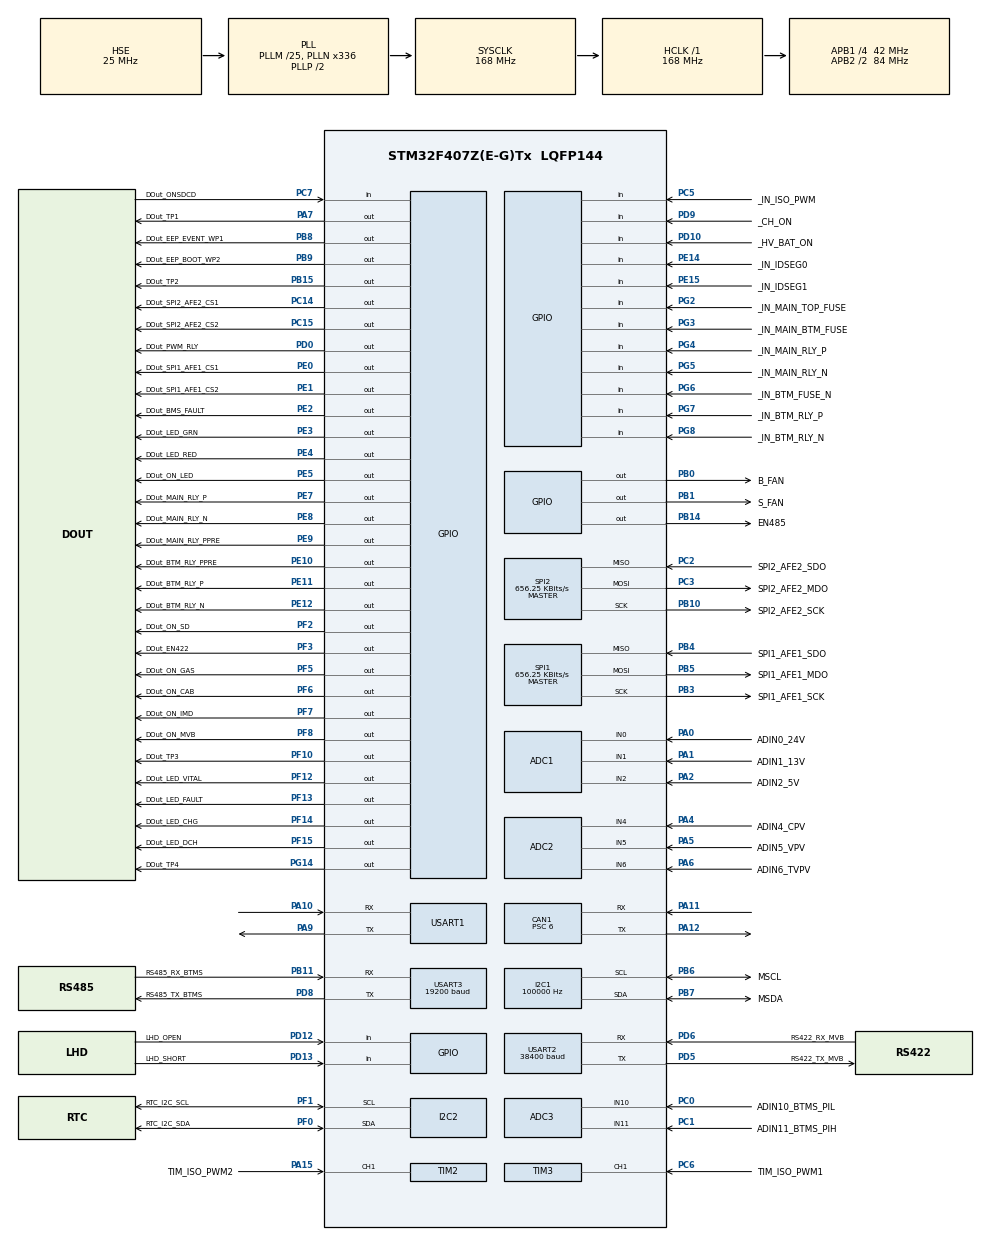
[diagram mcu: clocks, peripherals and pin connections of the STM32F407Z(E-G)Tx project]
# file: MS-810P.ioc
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ADC1.Channel-1\#ChannelRegularConversion=ADC_CHANNEL_0
ADC1.Channel-2\#ChannelRegularConversion=ADC_CHANNEL_1
ADC1.Channel-3\#ChannelRegularConversion=ADC_CHANNEL_2
ADC1.Channel-4\#ChannelRegularConversion=ADC_CHANNEL_VREFINT
ADC1.ClockPrescaler=ADC_CLOCK_SYNC_PCLK_DIV4
ADC1.ContinuousConvMode=ENABLE
ADC1.DMAContinuousRequests=ENABLE
ADC1.EOCSelection=ADC_EOC_SEQ_CONV
ADC1.NbrOfConversion=4
ADC1.NbrOfConversionFlag=1
ADC1.Rank-1\#ChannelRegularConversion=1
ADC1.Rank-2\#ChannelRegularConversion=2
ADC1.Rank-3\#ChannelRegularConversion=3
ADC1.Rank-4\#ChannelRegularConversion=4
ADC1.SamplingTime-1\#ChannelRegularConversion=ADC_SAMPLETIME_480CYCLES
ADC1.SamplingTime-2\#ChannelRegularConversion=ADC_SAMPLETIME_480CYCLES
ADC1.SamplingTime-3\#ChannelRegularConversion=ADC_SAMPLETIME_480CYCLES
ADC1.SamplingTime-4\#ChannelRegularConversion=ADC_SAMPLETIME_480CYCLES
ADC1.ScanConvMode=ENABLE
ADC1.master=1
ADC2.Channel-2\#ChannelRegularConversion=ADC_CHANNEL_4
ADC2.Channel-3\#ChannelRegularConversion=ADC_CHANNEL_5
ADC2.Channel-4\#ChannelRegularConversion=ADC_CHANNEL_6
ADC2.ClockPrescaler=ADC_CLOCK_SYNC_PCLK_DIV4
ADC2.ContinuousConvMode=ENABLE
ADC2.DMAContinuousRequests=ENABLE
ADC2.EOCSelection=ADC_EOC_SEQ_CONV
ADC2.NbrOfConversion=3
ADC2.NbrOfConversionFlag=1
ADC2.Rank-2\#ChannelRegularConversion=1
ADC2.Rank-3\#ChannelRegularConversion=2
ADC2.Rank-4\#ChannelRegularConversion=3
ADC2.SamplingTime-2\#ChannelRegularConversion=ADC_SAMPLETIME_480CYCLES
ADC2.SamplingTime-3\#ChannelRegularConversion=ADC_SAMPLETIME_480CYCLES
ADC2.SamplingTime-4\#ChannelRegularConversion=ADC_SAMPLETIME_480CYCLES
ADC2.ScanConvMode=ENABLE
ADC3.Channel-1\#ChannelRegularConversion=ADC_CHANNEL_10
ADC3.Channel-2\#ChannelRegularConversion=ADC_CHANNEL_11
ADC3.ClockPrescaler=ADC_CLOCK_SYNC_PCLK_DIV4
ADC3.ContinuousConvMode=ENABLE
ADC3.DMAContinuousRequests=ENABLE
ADC3.EOCSelection=ADC_EOC_SEQ_CONV
ADC3.NbrOfConversion=2
ADC3.NbrOfConversionFlag=1
ADC3.Rank-1\#ChannelRegularConversion=1
ADC3.Rank-2\#ChannelRegularConversion=2
ADC3.SamplingTime-1\#ChannelRegularConversion=ADC_SAMPLETIME_480CYCLES
ADC3.SamplingTime-2\#ChannelRegularConversion=ADC_SAMPLETIME_480CYCLES
ADC3.ScanConvMode=ENABLE
CAN1.BS1=CAN_BS1_11TQ
CAN1.BS2=CAN_BS2_2TQ
CAN1.CalculateBaudRate=500000
CAN1.CalculateTimeBit=2000
CAN1.CalculateTimeQuantum=142.85714285714286
CAN1.Prescaler=6
Dma.ADC1.7.Direction=DMA_PERIPH_TO_MEMORY
Dma.ADC1.7.FIFOMode=DMA_FIFOMODE_DISABLE
Dma.ADC1.7.Instance=DMA2_Stream4
Dma.ADC1.7.MemDataAlignment=DMA_MDATAALIGN_HALFWORD
Dma.ADC1.7.MemInc=DMA_MINC_ENABLE
Dma.ADC1.7.Mode=DMA_CIRCULAR
Dma.ADC1.7.PeriphDataAlignment=DMA_PDATAALIGN_HALFWORD
Dma.ADC1.7.PeriphInc=DMA_PINC_DISABLE
Dma.ADC1.7.Priority=DMA_PRIORITY_LOW
Dma.ADC2.10.Direction=DMA_PERIPH_TO_MEMORY
Dma.ADC2.10.FIFOMode=DMA_FIFOMODE_DISABLE
Dma.ADC2.10.Instance=DMA2_Stream2
Dma.ADC2.10.MemDataAlignment=DMA_MDATAALIGN_HALFWORD
Dma.ADC2.10.MemInc=DMA_MINC_ENABLE
Dma.ADC2.10.Mode=DMA_CIRCULAR
Dma.ADC2.10.PeriphDataAlignment=DMA_PDATAALIGN_HALFWORD
Dma.ADC2.10.PeriphInc=DMA_PINC_DISABLE
Dma.ADC2.10.Priority=DMA_PRIORITY_LOW
Dma.ADC3.11.Direction=DMA_PERIPH_TO_MEMORY
Dma.ADC3.11.FIFOMode=DMA_FIFOMODE_DISABLE
Dma.ADC3.11.Instance=DMA2_Stream1
Dma.ADC3.11.MemDataAlignment=DMA_MDATAALIGN_HALFWORD
Dma.ADC3.11.MemInc=DMA_MINC_ENABLE
Dma.ADC3.11.Mode=DMA_CIRCULAR
Dma.ADC3.11.PeriphDataAlignment=DMA_PDATAALIGN_HALFWORD
Dma.ADC3.11.PeriphInc=DMA_PINC_DISABLE
Dma.ADC3.11.Priority=DMA_PRIORITY_LOW
Dma.Request0=SPI1_TX
Dma.Request1=SPI1_RX
Dma.Request10=ADC2
Dma.Request11=ADC3
Dma.Request2=SPI2_TX
Dma.Request3=SPI2_RX
Dma.Request4=USART2_TX
Dma.Request5=USART2_RX
Dma.Request6=USART3_RX
Dma.Request7=ADC1
Dma.Request8=USART1_RX
Dma.Request9=USART1_TX
Dma.SPI1_RX.1.Direction=DMA_PERIPH_TO_MEMORY
Dma.SPI1_RX.1.FIFOMode=DMA_FIFOMODE_DISABLE
Dma.SPI1_RX.1.Instance=DMA2_Stream0
Dma.SPI1_RX.1.MemDataAlignment=DMA_MDATAALIGN_BYTE
Dma.SPI1_RX.1.MemInc=DMA_MINC_ENABLE
Dma.SPI1_RX.1.Mode=DMA_NORMAL
Dma.SPI1_RX.1.PeriphDataAlignment=DMA_PDATAALIGN_BYTE
Dma.SPI1_RX.1.PeriphInc=DMA_PINC_DISABLE
Dma.SPI1_RX.1.Priority=DMA_PRIORITY_LOW
Dma.SPI1_TX.0.Direction=DMA_MEMORY_TO_PERIPH
Dma.SPI1_TX.0.FIFOMode=DMA_FIFOMODE_DISABLE
Dma.SPI1_TX.0.Instance=DMA2_Stream3
Dma.SPI1_TX.0.MemDataAlignment=DMA_MDATAALIGN_BYTE
Dma.SPI1_TX.0.MemInc=DMA_MINC_ENABLE
Dma.SPI1_TX.0.Mode=DMA_NORMAL
Dma.SPI1_TX.0.PeriphDataAlignment=DMA_PDATAALIGN_BYTE
Dma.SPI1_TX.0.PeriphInc=DMA_PINC_DISABLE
Dma.SPI1_TX.0.Priority=DMA_PRIORITY_LOW
Dma.SPI2_RX.3.Direction=DMA_PERIPH_TO_MEMORY
Dma.SPI2_RX.3.FIFOMode=DMA_FIFOMODE_DISABLE
Dma.SPI2_RX.3.Instance=DMA1_Stream3
Dma.SPI2_RX.3.MemDataAlignment=DMA_MDATAALIGN_BYTE
Dma.SPI2_RX.3.MemInc=DMA_MINC_ENABLE
Dma.SPI2_RX.3.Mode=DMA_NORMAL
Dma.SPI2_RX.3.PeriphDataAlignment=DMA_PDATAALIGN_BYTE
Dma.SPI2_RX.3.PeriphInc=DMA_PINC_DISABLE
Dma.SPI2_RX.3.Priority=DMA_PRIORITY_LOW
Dma.SPI2_TX.2.Direction=DMA_MEMORY_TO_PERIPH
Dma.SPI2_TX.2.FIFOMode=DMA_FIFOMODE_DISABLE
Dma.SPI2_TX.2.Instance=DMA1_Stream4
Dma.SPI2_TX.2.MemDataAlignment=DMA_MDATAALIGN_BYTE
Dma.SPI2_TX.2.MemInc=DMA_MINC_ENABLE
Dma.SPI2_TX.2.Mode=DMA_NORMAL
Dma.SPI2_TX.2.PeriphDataAlignment=DMA_PDATAALIGN_BYTE
Dma.SPI2_TX.2.PeriphInc=DMA_PINC_DISABLE
Dma.SPI2_TX.2.Priority=DMA_PRIORITY_LOW
Dma.USART1_RX.8.Direction=DMA_PERIPH_TO_MEMORY
Dma.USART1_RX.8.FIFOMode=DMA_FIFOMODE_DISABLE
Dma.USART1_RX.8.Instance=DMA2_Stream5
Dma.USART1_RX.8.MemDataAlignment=DMA_MDATAALIGN_BYTE
Dma.USART1_RX.8.MemInc=DMA_MINC_ENABLE
Dma.USART1_RX.8.Mode=DMA_CIRCULAR
Dma.USART1_RX.8.PeriphDataAlignment=DMA_PDATAALIGN_BYTE
Dma.USART1_RX.8.PeriphInc=DMA_PINC_DISABLE
Dma.USART1_RX.8.Priority=DMA_PRIORITY_LOW
Dma.USART1_TX.9.Direction=DMA_MEMORY_TO_PERIPH
Dma.USART1_TX.9.FIFOMode=DMA_FIFOMODE_DISABLE
Dma.USART1_TX.9.Instance=DMA2_Stream7
Dma.USART1_TX.9.MemDataAlignment=DMA_MDATAALIGN_BYTE
Dma.USART1_TX.9.MemInc=DMA_MINC_ENABLE
Dma.USART1_TX.9.Mode=DMA_NORMAL
Dma.USART1_TX.9.PeriphDataAlignment=DMA_PDATAALIGN_BYTE
Dma.USART1_TX.9.PeriphInc=DMA_PINC_DISABLE
Dma.USART1_TX.9.Priority=DMA_PRIORITY_LOW
Dma.USART2_RX.5.Direction=DMA_PERIPH_TO_MEMORY
Dma.USART2_RX.5.FIFOMode=DMA_FIFOMODE_DISABLE
Dma.USART2_RX.5.Instance=DMA1_Stream5
Dma.USART2_RX.5.MemDataAlignment=DMA_MDATAALIGN_BYTE
Dma.USART2_RX.5.MemInc=DMA_MINC_ENABLE
Dma.USART2_RX.5.Mode=DMA_NORMAL
Dma.USART2_RX.5.PeriphDataAlignment=DMA_PDATAALIGN_BYTE
Dma.USART2_RX.5.PeriphInc=DMA_PINC_DISABLE
Dma.USART2_RX.5.Priority=DMA_PRIORITY_LOW
Dma.USART2_TX.4.Direction=DMA_MEMORY_TO_PERIPH
Dma.USART2_TX.4.FIFOMode=DMA_FIFOMODE_DISABLE
Dma.USART2_TX.4.Instance=DMA1_Stream6
Dma.USART2_TX.4.MemDataAlignment=DMA_MDATAALIGN_BYTE
Dma.USART2_TX.4.MemInc=DMA_MINC_ENABLE
Dma.USART2_TX.4.Mode=DMA_NORMAL
Dma.USART2_TX.4.PeriphDataAlignment=DMA_PDATAALIGN_BYTE
Dma.USART2_TX.4.PeriphInc=DMA_PINC_DISABLE
Dma.USART2_TX.4.Priority=DMA_PRIORITY_LOW
Dma.USART3_RX.6.Direction=DMA_PERIPH_TO_MEMORY
Dma.USART3_RX.6.FIFOMode=DMA_FIFOMODE_DISABLE
Dma.USART3_RX.6.Instance=DMA1_Stream1
Dma.USART3_RX.6.MemDataAlignment=DMA_MDATAALIGN_BYTE
Dma.USART3_RX.6.MemInc=DMA_MINC_ENABLE
Dma.USART3_RX.6.Mode=DMA_NORMAL
Dma.USART3_RX.6.PeriphDataAlignment=DMA_PDATAALIGN_BYTE
Dma.USART3_RX.6.PeriphInc=DMA_PINC_DISABLE
Dma.USART3_RX.6.Priority=DMA_PRIORITY_LOW
I2C1.ClockSpeed=100000
I2C1.I2C_Mode=I2C_Standard
Mcu.Family=STM32F4
Mcu.Name=STM32F407Z(E-G)Tx
Mcu.Package=LQFP144
NVIC.CAN1_RX0_IRQn=true\:4\:0\:true\:false\:true\:true\:true\:true
NVIC.CAN1_TX_IRQn=true\:4\:0\:true\:false\:true\:true\:true\:true
NVIC.DMA1_Stream1_IRQn=true\:6\:0\:true\:false\:true\:false\:true\:true
NVIC.DMA1_Stream3_IRQn=true\:3\:0\:true\:false\:true\:false\:true\:true
NVIC.DMA1_Stream4_IRQn=true\:3\:0\:true\:false\:true\:false\:true\:true
NVIC.DMA1_Stream5_IRQn=true\:6\:0\:true\:false\:true\:false\:true\:true
NVIC.DMA1_Stream6_IRQn=true\:6\:0\:true\:false\:true\:false\:true\:true
NVIC.DMA2_Stream0_IRQn=true\:3\:0\:true\:false\:true\:false\:true\:true
NVIC.DMA2_Stream1_IRQn=true\:2\:0\:true\:false\:true\:false\:true\:true
NVIC.DMA2_Stream2_IRQn=true\:2\:0\:true\:false\:true\:false\:true\:true
NVIC.DMA2_Stream3_IRQn=true\:3\:0\:true\:false\:true\:false\:true\:true
NVIC.DMA2_Stream4_IRQn=true\:2\:0\:true\:false\:true\:false\:true\:true
NVIC.DMA2_Stream5_IRQn=true\:6\:0\:true\:false\:true\:false\:true\:true
NVIC.DMA2_Stream7_IRQn=true\:6\:0\:true\:false\:true\:false\:true\:true
NVIC.I2C1_EV_IRQn=true\:5\:0\:true\:false\:true\:true\:true\:true
NVIC.I2C2_ER_IRQn=true\:5\:0\:true\:false\:true\:true\:true\:true
NVIC.I2C2_EV_IRQn=true\:5\:0\:true\:false\:true\:true\:true\:true
NVIC.PriorityGroup=NVIC_PRIORITYGROUP_4
NVIC.TIM1_UP_TIM10_IRQn=true\:1\:0\:true\:false\:true\:true\:true\:true
NVIC.USART1_IRQn=true\:6\:0\:true\:false\:true\:true\:true\:true
NVIC.USART2_IRQn=true\:6\:0\:true\:false\:true\:true\:true\:true
NVIC.USART3_IRQn=true\:6\:0\:true\:false\:true\:true\:true\:true
PA0-WKUP.GPIO_Label=ADIN0_24V
PA0-WKUP.Signal=ADCx_IN0
PA1.GPIO_Label=ADIN1_13V
PA1.Signal=ADCx_IN1
PA10.GPIO_ModeDefaultPP=GPIO_MODE_AF_PP
PA10.GPIO_PuPd=GPIO_NOPULL
PA10.GPIO_Speed=GPIO_SPEED_FREQ_VERY_HIGH
PA10.Mode=Asynchronous
PA10.Signal=USART1_RX
PA11.Mode=CAN_Activate
PA11.Signal=CAN1_RX
PA12.Mode=CAN_Activate
PA12.Signal=CAN1_TX
PA13.Mode=Serial_Wire
PA13.Signal=SYS_JTMS-SWDIO
PA14.Mode=Serial_Wire
PA14.Signal=SYS_JTCK-SWCLK
PA15.GPIO_Label=TIM_ISO_PWM2
PA15.GPIO_ModeDefaultPP=GPIO_MODE_AF_PP
PA15.GPIO_PuPd=GPIO_NOPULL
PA15.GPIO_Speed=GPIO_SPEED_FREQ_LOW
PA15.Signal=S_TIM2_CH1_ETR
PA2.GPIO_Label=ADIN2_5V
PA2.Signal=ADCx_IN2
PA4.GPIO_Label=ADIN4_CPV
PA4.Signal=ADCx_IN4
PA5.GPIO_Label=ADIN5_VPV
PA5.Signal=ADCx_IN5
PA6.GPIO_Label=ADIN6_TVPV
PA6.Signal=ADCx_IN6
PA7.GPIO_Label=DOut_TP1
PA7.Signal=GPIO_Output
PA9.GPIO_ModeDefaultPP=GPIO_MODE_AF_PP
PA9.GPIO_PuPd=GPIO_NOPULL
PA9.GPIO_Speed=GPIO_SPEED_FREQ_VERY_HIGH
PA9.Mode=Asynchronous
PA9.Signal=USART1_TX
PB0.GPIO_Label=B_FAN
PB0.Signal=GPIO_Output
PB1.GPIO_Label=S_FAN
PB1.Signal=GPIO_Output
PB10.GPIO_Label=SPI2_AFE2_SCK
PB10.Mode=Full_Duplex_Master
PB10.Signal=SPI2_SCK
PB11.GPIO_Label=RS485_RX_BTMS
PB11.Mode=Asynchronous
PB11.Signal=USART3_RX
PB14.GPIO_Label=EN485
PB14.Signal=GPIO_Output
PB15.GPIO_Label=DOut_TP2
PB15.Signal=GPIO_Output
PB3.GPIO_Label=SPI1_AFE1_SCK
PB3.Mode=Full_Duplex_Master
PB3.Signal=SPI1_SCK
PB4.GPIO_Label=SPI1_AFE1_SDO
PB4.Mode=Full_Duplex_Master
PB4.Signal=SPI1_MISO
PB5.GPIO_Label=SPI1_AFE1_MDO
PB5.Mode=Full_Duplex_Master
PB5.Signal=SPI1_MOSI
PB6.GPIO_Label=MSCL
PB6.Mode=I2C
PB6.Signal=I2C1_SCL
PB7.GPIO_Label=MSDA
PB7.Mode=I2C
PB7.Signal=I2C1_SDA
PB8.GPIO_Label=DOut_EEP_EVENT_WP1
PB8.Signal=GPIO_Output
PB9.GPIO_Label=DOut_EEP_BOOT_WP2
PB9.Signal=GPIO_Output
PC0.GPIO_Label=ADIN10_BTMS_PIL
PC0.Signal=ADCx_IN10
PC1.GPIO_Label=ADIN11_BTMS_PIH
PC1.Signal=ADCx_IN11
PC14-OSC32_IN.GPIO_Label=DOut_SPI2_AFE2_CS1
PC14-OSC32_IN.Signal=GPIO_Output
PC15-OSC32_OUT.GPIO_Label=DOut_SPI2_AFE2_CS2
PC15-OSC32_OUT.Signal=GPIO_Output
PC2.GPIO_Label=SPI2_AFE2_SDO
PC2.Mode=Full_Duplex_Master
PC2.Signal=SPI2_MISO
PC3.GPIO_Label=SPI2_AFE2_MDO
PC3.Mode=Full_Duplex_Master
PC3.Signal=SPI2_MOSI
PC5.GPIO_Label=_IN_ISO_PWM
PC5.Signal=GPIO_Input
PC6.GPIO_Label=TIM_ISO_PWM1
PC6.Signal=S_TIM3_CH1
PC7.GPIO_Label=DOut_ONSDCD
PC7.Signal=GPIO_Input
PD0.GPIO_Label=DOut_PWM_RLY
PD0.Signal=GPIO_Output
PD10.GPIO_Label=_HV_BAT_ON
PD10.Signal=GPIO_Input
PD12.GPIO_Label=LHD_OPEN
PD12.Signal=GPIO_Input
PD13.GPIO_Label=LHD_SHORT
PD13.Signal=GPIO_Input
PD5.GPIO_Label=RS422_TX_MVB
PD5.Mode=Asynchronous
PD5.Signal=USART2_TX
PD6.GPIO_Label=RS422_RX_MVB
PD6.Mode=Asynchronous
PD6.Signal=USART2_RX
PD8.GPIO_Label=RS485_TX_BTMS
PD8.Mode=Asynchronous
PD8.Signal=USART3_TX
PD9.GPIO_Label=_CH_ON
PD9.Signal=GPIO_Input
PE0.GPIO_Label=DOut_SPI1_AFE1_CS1
PE0.Signal=GPIO_Output
PE1.GPIO_Label=DOut_SPI1_AFE1_CS2
PE1.Signal=GPIO_Output
PE10.GPIO_Label=DOut_BTM_RLY_PPRE
PE10.Signal=GPIO_Output
PE11.GPIO_Label=DOut_BTM_RLY_P
PE11.Signal=GPIO_Output
PE12.GPIO_Label=DOut_BTM_RLY_N
PE12.Signal=GPIO_Output
PE14.GPIO_Label=_IN_IDSEG0
PE14.Signal=GPIO_Input
PE15.GPIO_Label=_IN_IDSEG1
PE15.Signal=GPIO_Input
PE2.GPIO_Label=DOut_BMS_FAULT
PE2.Signal=GPIO_Output
PE3.GPIO_Label=DOut_LED_GRN
PE3.Signal=GPIO_Output
PE4.GPIO_Label=DOut_LED_RED
PE4.Signal=GPIO_Output
PE5.GPIO_Label=DOut_ON_LED
PE5.Signal=GPIO_Output
PE7.GPIO_Label=DOut_MAIN_RLY_P
PE7.Signal=GPIO_Output
PE8.GPIO_Label=DOut_MAIN_RLY_N
PE8.Signal=GPIO_Output
PE9.GPIO_Label=DOut_MAIN_RLY_PPRE
PE9.Signal=GPIO_Output
PF0.GPIO_Label=RTC_I2C_SDA
PF0.Mode=I2C
PF0.Signal=I2C2_SDA
PF1.GPIO_Label=RTC_I2C_SCL
PF1.Mode=I2C
PF1.Signal=I2C2_SCL
PF10.GPIO_Label=DOut_TP3
PF10.Signal=GPIO_Output
PF12.GPIO_Label=DOut_LED_VITAL
PF12.Signal=GPIO_Output
PF13.GPIO_Label=DOut_LED_FAULT
PF13.Signal=GPIO_Output
PF14.GPIO_Label=DOut_LED_CHG
PF14.Signal=GPIO_Output
PF15.GPIO_Label=DOut_LED_DCH
PF15.Signal=GPIO_Output
PF2.GPIO_Label=DOut_ON_SD
PF2.Signal=GPIO_Output
PF3.GPIO_Label=DOut_EN422
PF3.Signal=GPIO_Output
PF5.GPIO_Label=DOut_ON_GAS
PF5.Signal=GPIO_Output
PF6.GPIO_Label=DOut_ON_CAB
PF6.Signal=GPIO_Output
PF7.GPIO_Label=DOut_ON_IMD
PF7.Signal=GPIO_Output
PF8.GPIO_Label=DOut_ON_MVB
PF8.Signal=GPIO_Output
PG14.GPIO_Label=DOut_TP4
PG14.Signal=GPIO_Output
PG2.GPIO_Label=_IN_MAIN_TOP_FUSE
PG2.Signal=GPIO_Input
PG3.GPIO_Label=_IN_MAIN_BTM_FUSE
PG3.Signal=GPIO_Input
PG4.GPIO_Label=_IN_MAIN_RLY_P
PG4.Signal=GPIO_Input
PG5.GPIO_Label=_IN_MAIN_RLY_N
PG5.Signal=GPIO_Input
PG6.GPIO_Label=_IN_BTM_FUSE_N
PG6.Signal=GPIO_Input
PG7.GPIO_Label=_IN_BTM_RLY_P
PG7.Signal=GPIO_Input
PG8.GPIO_Label=_IN_BTM_RLY_N
PG8.Signal=GPIO_Input
PH0-OSC_IN.Mode=HSE-External-Oscillator
PH0-OSC_IN.Signal=RCC_OSC_IN
PH1-OSC_OUT.Mode=HSE-External-Oscillator
PH1-OSC_OUT.Signal=RCC_OSC_OUT
ProjectManager.HeapSize=0x200
ProjectManager.StackSize=0x400
ProjectManager.TargetToolchain=STM32CubeIDE
RCC.48MHZClocksFreq_Value=48000000
RCC.AHBFreq_Value=168000000
RCC.APB1CLKDivider=RCC_HCLK_DIV4
RCC.APB1Freq_Value=42000000
RCC.APB1TimFreq_Value=84000000
RCC.APB2CLKDivider=RCC_HCLK_DIV2
RCC.APB2Freq_Value=84000000
RCC.APB2TimFreq_Value=168000000
RCC.CortexFreq_Value=168000000
RCC.HCLKFreq_Value=168000000
RCC.HSE_VALUE=25000000
RCC.HSI_VALUE=16000000
RCC.LSE_VALUE=32768
RCC.PLLM=25
RCC.PLLN=336
RCC.PLLQ=7
RCC.PLLSourceVirtual=RCC_PLLSOURCE_HSE
RCC.SYSCLKFreq_VALUE=168000000
RCC.SYSCLKSource=RCC_SYSCLKSOURCE_PLLCLK
RCC.VCOOutputFreq_Value=336000000
SH.ADCx_IN0.0=ADC1_IN0,IN0
SH.ADCx_IN1.0=ADC1_IN1,IN1
SH.ADCx_IN10.0=ADC3_IN10,IN10
SH.ADCx_IN11.0=ADC3_IN11,IN11
SH.ADCx_IN2.0=ADC1_IN2,IN2
SH.ADCx_IN4.0=ADC2_IN4,IN4
SH.ADCx_IN5.0=ADC2_IN5,IN5
SH.ADCx_IN6.0=ADC2_IN6,IN6
SH.S_TIM2_CH1_ETR.0=TIM2_CH1,Input_Capture1_from_TI1
SH.S_TIM3_CH1.0=TIM3_CH1,Input_Capture1_from_TI1
SPI1.BaudRatePrescaler=SPI_BAUDRATEPRESCALER_128
SPI1.CLKPhase=SPI_PHASE_2EDGE
SPI1.CLKPolarity=SPI_POLARITY_HIGH
SPI1.CalculateBaudRate=656.25 KBits/s
SPI1.Direction=SPI_DIRECTION_2LINES
SPI1.Mode=SPI_MODE_MASTER
SPI1.VirtualType=VM_MASTER
SPI2.BaudRatePrescaler=SPI_BAUDRATEPRESCALER_64
SPI2.CLKPhase=SPI_PHASE_2EDGE
SPI2.CLKPolarity=SPI_POLARITY_HIGH
SPI2.CalculateBaudRate=656.25 KBits/s
SPI2.Direction=SPI_DIRECTION_2LINES
SPI2.Mode=SPI_MODE_MASTER
SPI2.VirtualType=VM_MASTER
TIM1.Period=1000-1
TIM1.Prescaler=168-1
TIM2.Channel-Input_Capture1_from_TI1=TIM_CHANNEL_1
TIM3.Channel-Input_Capture1_from_TI1=TIM_CHANNEL_1
USART1.VirtualMode=VM_ASYNC
USART2.BaudRate=38400
USART2.VirtualMode=VM_ASYNC
USART3.BaudRate=19200
USART3.VirtualMode=VM_ASYNC
VP_ADC1_Vref_Input.Mode=IN-Vrefint
VP_IWDG_VS_IWDG.Mode=IWDG_Activate
VP_TIM1_VS_ClockSourceINT.Mode=Internal
VP_TIM1_VS_ClockSourceITR.Mode=TriggerSource_ITR0
VP_WWDG_VS_WWDG.Mode=WWDG_Activate
board=custom

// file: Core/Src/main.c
/* USER CODE BEGIN Header */
/**
  ******************************************************************************
  * @file           : main.c
  * @brief          : Main program body
  ******************************************************************************
  * @attention
  *
  * Copyright (c) 2025 STMicroelectronics.
  * All rights reserved.
  *
  * This software is licensed under terms that can be found in the LICENSE file
  * in the root directory of this software component.
  * If no LICENSE file comes with this software, it is provided AS-IS.
  *
  ******************************************************************************
  */
/* USER CODE END Header */
#include "main.h"
#include "adc.h"
#include "can.h"
#include "dma.h"
#include "i2c.h"
#include "iwdg.h"
#include "spi.h"
#include "tim.h"
#include "usart.h"
#include "wwdg.h"
#include "gpio.h"

/* USER CODE BEGIN Includes */
#include "ms_main.h"

/* USER CODE END Includes */

void SystemClock_Config(void);

int main(void)
{

  /* MCU Configuration--------------------------------------------------------*/

  /* Reset of all peripherals, Initializes the Flash interface and the Systick. */
  HAL_Init();

  /* Configure the system clock */
  SystemClock_Config();

  /* Initialize all configured peripherals */
  MX_GPIO_Init();
  MX_DMA_Init();
  MX_ADC1_Init();
  MX_ADC2_Init();
  MX_ADC3_Init();
  MX_CAN1_Init();
  MX_I2C1_Init();
  MX_SPI1_Init();
  MX_TIM2_Init();
  MX_TIM3_Init();
  MX_USART1_UART_Init();
  MX_USART2_UART_Init();
  MX_USART3_UART_Init();
  MX_I2C2_Init();
  MX_SPI2_Init();
  MX_TIM1_Init();
  //MX_IWDG_Init();
  //MX_WWDG_Init();
  /* USER CODE BEGIN 2 */
	HAL_TIM_Base_Start_IT(&htim1);
    DWT_Delay_Init();                                                                     //jkpark 2025-12-18 Delay?��?��?�� ?��?�� 추�?.
    ms_main();
  /* USER CODE END 2 */

  /* Infinite loop */
  while (1)
  {

  }
}

void SystemClock_Config(void)
{
  RCC_OscInitTypeDef RCC_OscInitStruct = {0};
  RCC_ClkInitTypeDef RCC_ClkInitStruct = {0};

  /** Configure the main internal regulator output voltage
  */
  __HAL_RCC_PWR_CLK_ENABLE();
  __HAL_PWR_VOLTAGESCALING_CONFIG(PWR_REGULATOR_VOLTAGE_SCALE1);

  /** Initializes the RCC Oscillators according to the specified parameters
  * in the RCC_OscInitTypeDef structure.
  */
  RCC_OscInitStruct.OscillatorType = RCC_OSCILLATORTYPE_LSI|RCC_OSCILLATORTYPE_HSE;
  RCC_OscInitStruct.HSEState = RCC_HSE_ON;
  RCC_OscInitStruct.LSIState = RCC_LSI_ON;
  RCC_OscInitStruct.PLL.PLLState = RCC_PLL_ON;
  RCC_OscInitStruct.PLL.PLLSource = RCC_PLLSOURCE_HSE;
  RCC_OscInitStruct.PLL.PLLM = 25;
  RCC_OscInitStruct.PLL.PLLN = 336;
  RCC_OscInitStruct.PLL.PLLP = RCC_PLLP_DIV2;
  RCC_OscInitStruct.PLL.PLLQ = 7;
  if (HAL_RCC_OscConfig(&RCC_OscInitStruct) != HAL_OK)
  {
    Error_Handler();
  }

  /** Initializes the CPU, AHB and APB buses clocks
  */
  RCC_ClkInitStruct.ClockType = RCC_CLOCKTYPE_HCLK|RCC_CLOCKTYPE_SYSCLK
                              |RCC_CLOCKTYPE_PCLK1|RCC_CLOCKTYPE_PCLK2;
  RCC_ClkInitStruct.SYSCLKSource = RCC_SYSCLKSOURCE_PLLCLK;
  RCC_ClkInitStruct.AHBCLKDivider = RCC_SYSCLK_DIV1;
  RCC_ClkInitStruct.APB1CLKDivider = RCC_HCLK_DIV4;
  RCC_ClkInitStruct.APB2CLKDivider = RCC_HCLK_DIV2;

  if (HAL_RCC_ClockConfig(&RCC_ClkInitStruct, FLASH_LATENCY_5) != HAL_OK)
  {
    Error_Handler();
  }
}

void Error_Handler(void)
{
  __disable_irq();
  while (1)
  {
  }
}
